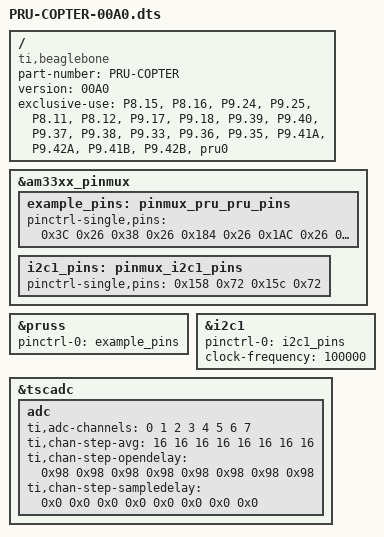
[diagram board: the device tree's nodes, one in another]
// This DTS overlay sets up four input and four output pins for use by  
 // PRU0 via its Enhanced GPIO mode 
 // Inputs for signals from receiver are:
 // BB_Header	Register bit	DT Offset	Pinmux mode
 // P8_15 	R31 bit 15	0x03C		Mode_6
 // P8_16 	R31 bit 14	0x038		Mode_6
 // P9_24 	R31 bit 16	0x184		Mode_6
 // P9_25 	R31 bit 7	0x1AC		Mode_6

 // Outputs, which are references to ESCs are:
 // BB_Header	Register bit	DT Offset	Pinmux mode
 // P9_42	R30 bit 4	  0x1A8		Mode_5
 // P9_41 R30 bit 6   0x1A0  Mode_5
 // P8_12	R30 bit 14 	0x030		Mode_6
 // P8_13	R30 bit 15 	0x034		Mode_6
   
 // Save this file wherever you want (but I recommend /lib/firmware), as  
 // "PRU-COPTER-00A0.dts".
   
 // Compile with:
 // dtc -O dtb -I dts -o /lib/firmware/PRU-COPTER-00A0.dtbo -b 0 -@ PRU-COPTER-00A0.dts  
   
 // You'll have to reboot, after which you can do this as root to activate it:  
 // echo PRU-COPTER > /sys/devices/bone_capemgr.?/slots  
 
 // Check with
 // cat /sys/devices/bone_capemgr.9/slots
 
 /dts-v1/;  
 /plugin/;  
 
 / {  
   // This determines which boards can use this DTS overlay  
   compatible = "ti,beaglebone", "ti,beaglebone-green", "ti,beaglebone-black";  
   
   // I think part-number is supposed to correspond with the filename,  
   // so we'd save this as "PRU-COPTER-00A0.dts".  
   part-number = "PRU-COPTER";  
   
   // This always seems to be 00A0, and all the .dtbo files in /lib/firmware  
   // seem to be named foo-00A0.dtbo, but then are loaded without that suffix.  So
   // for foo-00A0.dtbo we'd do 'echo foo > /sys/devices/bone_capemgr.?/slots'
   version = "00A0";
   
   // List the pins and resources we'll be using. This table:  
   // http://elinux.org/Ti_AM33XX_PRUSSv2#Beaglebone_PRU_connections_and_modes  
   // shows which pins can be used with PRU0 and PRU1 for input and output via  
   // registers R31 and R30.  
   // Beware: Many other PRU EGP pins are reserved by HDMI or onboard flash, which  
   // would need to be disabled first by editing uEnv.txt and rebooting.  
   exclusive-use =  
      "P8.15", "P8.16", "P9.24", "P9.25", "P8.11", "P8.12", "P9.17", "P9.18", "P9.39", "P9.40", "P9.37", "P9.38", "P9.33", "P9.36", "P9.35", "P9.41A", "P9.42A", "P9.41B", "P9.42B", "pru0";  
   
   fragment@0 {  
    target = <&am33xx_pinmux>;  
    __overlay__ {  
      example_pins: pinmux_pru_pru_pins {  
   
       // The offset and mode for pins also come from the table linked above.
       //  
       // That table gives offset 0x34 for P8_11, and 0x38 for P8_16.
       // It also shows us we want pinmux mode 5 for output mode,  
       // and pinmux mode 6 for input mode.
       // 
       // Table 9-60 in the TRM: http://www.ti.com/lit/ug/spruh73l/spruh73l.pdf  
       // helps us calculate the rest of the configuration value.  
       //  
       // For outputs, the other fields are all 0, so the value is just 0x06.  
       //  
       // For inputs we also set bit 5, yielding  
       // a value of 0x26. We could also set bits 3 and 4 to enable a pullup  
       // or pulldown.  
       pinctrl-single,pins = < 
       	0x3C 	 0x26
       	0x38 	 0x26
       	0x184 	0x26
       	0x1AC	 0x26
       	0x1B4  0x27
       	0x164  0x27
       	0x1A0	 0x05
       	0x1A8	 0x05
       	0x030 	0x06
       	0x034	 0x06
       >;  
      };  
    };  
   };  
   
   // This enables the PRU and assigns the GPIO pins to it for use in EGP mode.  
   fragment@1 {  
    target = <&pruss>;  
    __overlay__ {  
      status = "okay";  
      pinctrl-names = "default";  
      pinctrl-0 = <&example_pins>;  
    };  
   };  
 
   fragment@2 {  
    target = <&am33xx_pinmux>;  
    __overlay__ {  
      i2c1_pins: pinmux_i2c1_pins {  
       pinctrl-single,pins = < 
       	0x158  0x72     // P9-18 (B16) spi0_d1.I2C1_SDA, SLEWCTRL_SLOW | INPUT_PULLUP | MODE2
        0x15c  0x72     // P9-17 (A16) spi0_cs0.I2C1_SCL, SLEWCTRL_SLOW | INPUT_PULLUP | MODE2
       >;  
      };  
    };  
   };  
   
   fragment@3 {
    target = <&i2c1>;
    __overlay__ {
      status = "okay";
      pinctrl-names = "default";  
      pinctrl-0 = <&i2c1_pins>;
      clock-frequency = <100000>;
    };
  };
  
     fragment@4 {
       target = <&tscadc>;
       __overlay__ {
          status = "okay";
          adc{
         				ti,adc-channels = <0 1 2 3 4 5 6 7>;
         				ti,chan-step-avg = <16 16 16 16 16 16 16 16>;
         				ti,chan-step-opendelay = <0x98 0x98 0x98 0x98 0x98 0x98 0x98 0x98>;
         				ti,chan-step-sampledelay = <0x0 0x0 0x0 0x0 0x0 0x0 0x0 0x0>;
          };
       };
    };
}; 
